# nrf54h20_engb_sysctrl register map
Vendor: Nordic Semiconductor; Series: nRF54h; File version: 1
Registers are 32-bit, read-write, reset 0x0 unless marked. A register's access mark holds for its fields unless they carry their own. Offsets are from the block's base; [hi:lo] are bit positions; lines under a group give offsets from that group; 'fields as' and 'values as' point back to an identical list.

## VDETAO1V8 — VDETAO1V8 peripheral
Base 0x5F970000
0x00 TASKS_PWRUP wo — Power up voltage detector
  [0] TASKS_PWRUP
    1=Trigger task
0x04 TASKS_PWRDOWN wo — Power down voltage detector
  [0] TASKS_PWRDOWN
    1=Trigger task
0x100 EVENTS_READY — Power up done
  [0] EVENTS_READY
    0=NotGenerated (Event not generated); 1=Generated (Event generated)
0x104 EVENTS_SETTLED — Settled flag for MODE handshake
  [0] EVENTS_SETTLED
    values as EVENTS_READY.EVENTS_READY
0x108 EVENTS_BROWNOUTHIGH — Brownout detector high level detected voltage below high threshold
  [0] EVENTS_BROWNOUTHIGH
    values as EVENTS_READY.EVENTS_READY
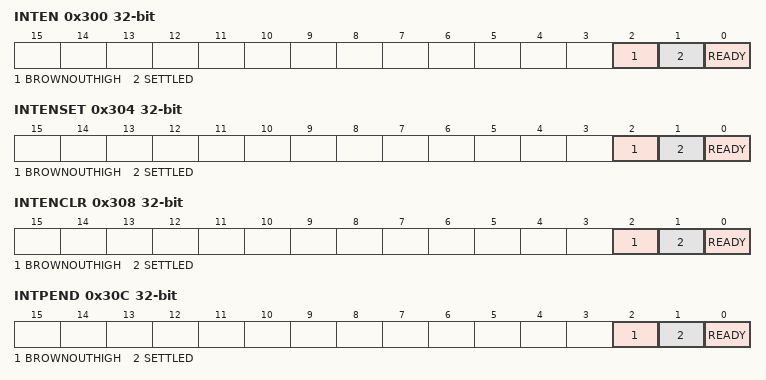
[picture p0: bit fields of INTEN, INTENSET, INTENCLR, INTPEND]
0x300 INTEN — Enable or disable interrupt
  [all] fields
    0=Disabled; 1=Enabled
  [2] BROWNOUTHIGH — Enable or disable interrupt for event BROWNOUTHIGH
  [1] SETTLED — Enable or disable interrupt for event SETTLED
  [0] READY — Enable or disable interrupt for event READY
0x304 INTENSET — Enable interrupt
  [all] fields
    on read: 0=Disabled (Read: Disabled); 1=Enabled (Read: Enabled) | on write: 1=Set (Enable)
  [2] BROWNOUTHIGH — Write '1' to enable interrupt for event BROWNOUTHIGH
  [1] SETTLED — Write '1' to enable interrupt for event SETTLED
  [0] READY — Write '1' to enable interrupt for event READY
0x308 INTENCLR — Disable interrupt
  [all] fields
    on read: 0=Disabled (Read: Disabled); 1=Enabled (Read: Enabled) | on write: 1=Clear (Disable)
  [2] BROWNOUTHIGH — Write '1' to disable interrupt for event BROWNOUTHIGH
  [1] SETTLED — Write '1' to disable interrupt for event SETTLED
  [0] READY — Write '1' to disable interrupt for event READY
0x30C INTPEND ro — Pending interrupts
  [all] fields
    on read: 0=NotPending (Read: Not pending); 1=Pending (Read: Pending)
  [2] BROWNOUTHIGH — Read pending status of interrupt for event BROWNOUTHIGH
  [1] SETTLED — Read pending status of interrupt for event SETTLED
  [0] READY — Read pending status of interrupt for event READY
0x400 STATUS ro — Voltage detector status
  [1:0] MODE — Current voltage detector mode
    0=High power mode; 1=Low power mode; 2=Ultra-low power refresh mode
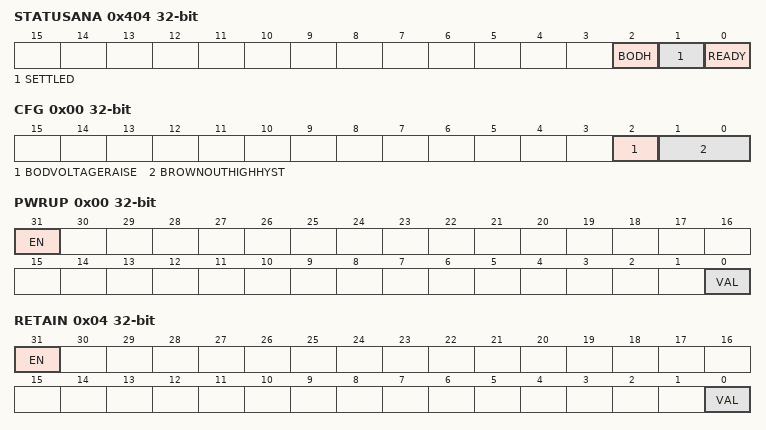
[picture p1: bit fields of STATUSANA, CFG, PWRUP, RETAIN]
0x404 STATUSANA ro — Status of analog module output signals
  [2] BODH — Current value of the BODH signal from the analog module
  [1] SETTLED — Current value of the SETTLED signal from the analog module
  [0] READY — Current value of the READY signal from the analog module
0x410 CONFIG group — Unspecified
  0x00 CFG — Voltage detector configuration
    [2] BODVOLTAGERAISE — Change in BODH and BODL threshold in ULPR and LP modes.
      0=No change in BODH and BODL threshold in ULPR and LP modes; 1=Raise (20mV voltage raise in BODH and BODL threshold in ULPR and LP modes.)
    [1:0] BROWNOUTHIGHHYST — Brown out detector high level hysteresis voltage value
      0=Val0V020 (Hysteresis voltage is 20mV); 1=Val0V040 (Hysteresis voltage is 40mV); 2=Val0V000 (Hysteresis voltage is 0mV); 3=Val0V010 (Hysteresis voltage is 10mV)
  0x04 BROWNOUTCONFIG — Brown out detector configuration
    [0] ENBROWNOUTLVLLOW — Enable Brown out detector low level
      0=Disabled (Brown out detector low level is disabled); 1=Enabled (Brown out detector low level is enabled)
0x440 TRIM group — Unspecified
  0x00 BROWNOUTLVLHIGH — Brown out detector high threshold voltage level
    [3:0] VAL — Threshold voltage value.
  0x04 BROWNOUTLVLLOW — Brown out detector low threshold voltage level
    [3:0] VAL — Threshold voltage value.
0x480 MIRROR reset 0x1 — Enable LOCK for mirrored registers
  [0] LOCK — Lock for mirrored registers
    0=Disabled (Lock disabled); 1=Enabled (Lock enabled)
0x484 MODE — Voltage detector mode
  [2:0] MODE
    0=Automatically handled by the peripheral; 1=High power mode; 2=Low power mode; 3=Ultra-low power refresh mode
0x500 OVERRIDE group — Unspecified
  0x00 PWRUP — Override the PWRUP signal to the analog module
    [31] EN — Enable the override
      0=Disabled (Override is disabled); 1=Enabled (Override is enabled)
    [0] VAL — Override value for the signal
  0x04 RETAIN — Override the RETAIN signal to the analog module
    fields as OVERRIDE.PWRUP
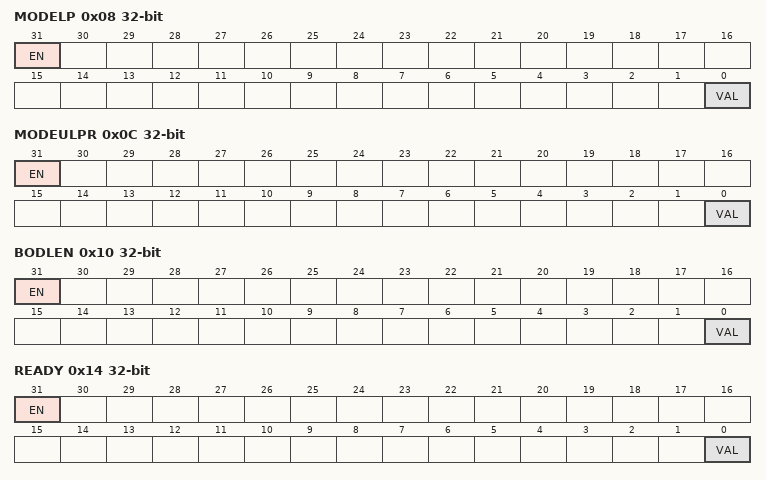
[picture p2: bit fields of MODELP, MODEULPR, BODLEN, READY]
  0x08 MODELP — Override the MODE_LP signal to the analog module
    fields as OVERRIDE.PWRUP
  0x0C MODEULPR — Override the MODE_ULPR signal to the analog module
    fields as OVERRIDE.PWRUP
  0x10 BODLEN — Override the BODL_EN signal to the analog module
    fields as OVERRIDE.PWRUP
  0x14 READY — Override the READY signal from the analog module
    [31] EN — Enable the override
      values as OVERRIDE.PWRUP.EN
    [0] VAL — Current value of the signal
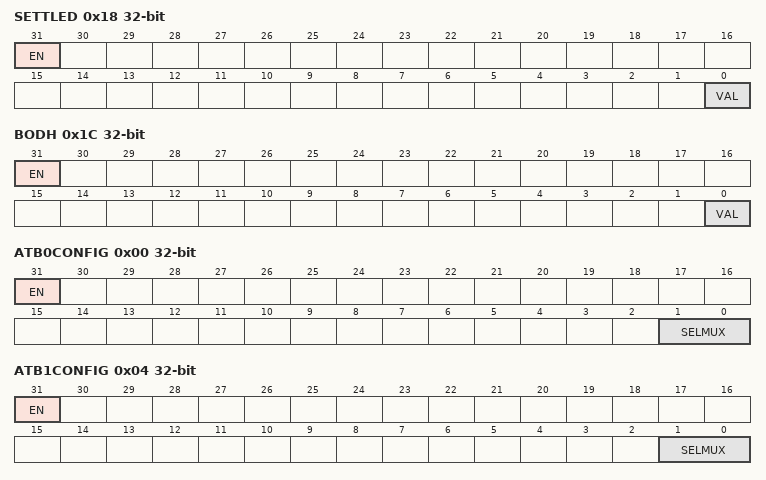
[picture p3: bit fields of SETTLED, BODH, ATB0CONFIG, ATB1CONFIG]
  0x18 SETTLED — Override the SETTLED signal from the analog module
    fields as OVERRIDE.READY
  0x1C BODH — Override the BODH signal from the analog module
    fields as OVERRIDE.READY
0x600 DFT group — Unspecified
  0x00 ATB0CONFIG — Analog Test Bus 0 (ATB0) configuration
    [31] EN — Enable the analog test bus
      0=Disabled (Analog test bus is disabled); 1=Enabled (Analog test bus is enabled)
    [1:0] SELMUX — Select multiplexer for ATB0
      0=IDBG1u (BOD CMP IDBG 1u current); 1=VSS (Connect VSS); 3=ConnectSenseVoltage (Connect internal sense voltage for BOD comparators)
  0x04 ATB1CONFIG — Analog Test Bus 1 (ATB1) configuration
    [31] EN — Enable the analog test bus
      values as DFT.ATB0CONFIG.EN
    [1:0] SELMUX — Select multiplexer for ATB1
      0=HiZ; 1=MonitorSenseVoltage (Monitor internal sense voltage for BOD comparators); 2=VREFH (Connect VREFH); 3=VREFL (Connect VREFL)
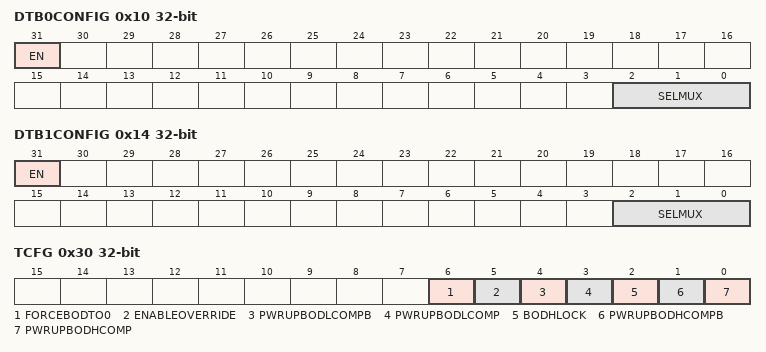
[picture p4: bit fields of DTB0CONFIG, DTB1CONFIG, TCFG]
  0x10 DTB0CONFIG — Digital Test Bus 0 (DTB0) configuration
    [31] EN — Enable the digital test bus
      0=Disabled (Digital test bus is disabled); 1=Enabled (Digital test bus is enabled)
    [2:0] SELMUX — Select multiplexer for DTB0
      0=MODE LP is selected; 1=MODE ULPR is selected; 2=BODLCompOutput (BODL comparator output is selected); 3=READY is selected; 4=BODLPWUP (Power up BODL is selected); 5=BODLBPWUP (Power up BODL bias is selected); 6=BODLLCKACKSW (BODL lock acknowledge is selected); 7=BODLCompOutputHS (BODL comparator output after handshake is selected)
  0x14 DTB1CONFIG — Digital Test Bus 1 (DTB1) configuration
    [31] EN — Enable the digital test bus
      values as DFT.DTB0CONFIG.EN
    [2:0] SELMUX — Select multiplexer for DTB1
      0=BODL ready is selected; 1=BODH ready is selected; 2=BODHCompOutput (BODH comparator output is selected); 3=SETTLED is selected; 4=BODHPwUp (Power up BODH is selected); 5=BODHPwUpB (Power up BODH bias is selected); 6=BODHLckReqSW (BODH Lock Req SW is selected); 7=BODLCompOutputHS (BODH comparator output after handshake is selected)
  0x1C DTB3CONFIG — Digital Test Bus 3 (DTB3) configuration
    [27] PWRUPDELTEST — Enable the PWRUP delay test circuit
      0=Disabled (PWRUP delay test circuit is disabled); 1=Enabled (PWRUP delay test circuit is enabled)
  0x30 TCFG — Test mode configuration
    [6] FORCEBODTO0 — Force BOD outputs to 0
      0=Disabled (Force disabled); 1=Enabled (Force enabled)
    [5] ENABLEOVERRIDE — Enable bits [4:0] in TCFG for overriding internal controls
      0=Disabled (Overriding internal controls disabled); 1=Enabled (Overriding internal controls enabled)
    [4] PWRUPBODLCOMPB — Power-up signal for BODL comparator bias
      0=Disabled (Power-up disabled); 1=Enabled (Power-up enabled)
    [3] PWRUPBODLCOMP — Power-up signal for BODL comparator
      0=Disabled (Power-up disabled); 1=Enabled (Power-up enabled)
    [2] BODHLOCK — BODH lock request signal
      0=Disabled (Lock request is 0); 1=Enabled (Lock request is 1)
    [1] PWRUPBODHCOMPB — Power-up signal for BODH comparator bias
      0=Disabled (Power-up disabled); 1=Enabled (Power-up enabled)
    [0] PWRUPBODHCOMP — Power-up signal for BODH comparator
      0=Disabled (Power-up disabled); 1=Enabled (Power-up enabled)
